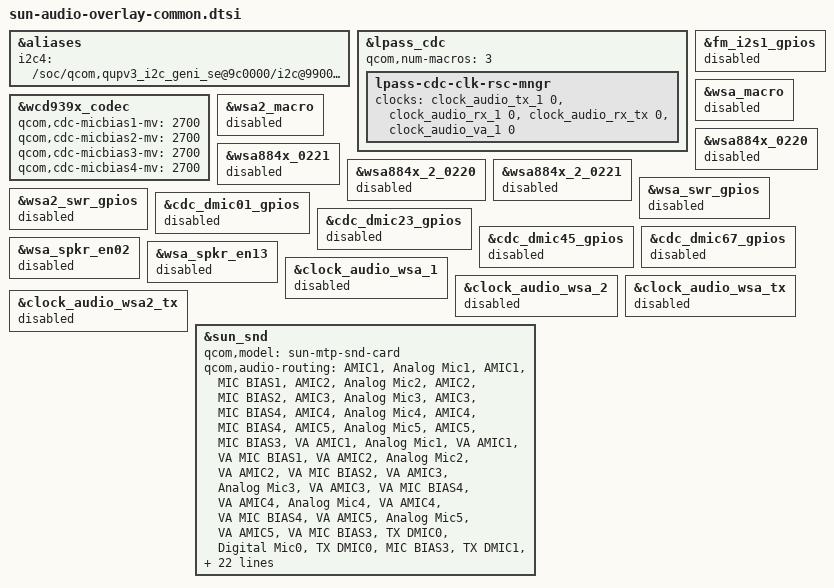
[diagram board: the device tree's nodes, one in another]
&aliases {
	i2c4 = "/soc/qcom,qupv3_i2c_geni_se@9c0000/i2c@990000";
};

&lpass_cdc {
	qcom,num-macros = <3>;
	lpass-cdc-clk-rsc-mngr {
	clock-names = "tx_core_clk", "rx_core_clk", "rx_tx_core_clk", "va_core_clk";
	clocks = <&clock_audio_tx_1 0>, <&clock_audio_rx_1 0>,
		<&clock_audio_rx_tx 0>, <&clock_audio_va_1 0>;
	};
};

&wcd939x_codec {
	qcom,cdc-micbias1-mv = <2700>;
	qcom,cdc-micbias2-mv = <2700>;
	qcom,cdc-micbias3-mv = <2700>;
	qcom,cdc-micbias4-mv = <2700>;
};

&fm_i2s1_gpios {
	status = "disabled";
};

&wsa_macro {
	status = "disabled";
};

&wsa2_macro {
	status = "disabled";
};

&wsa884x_0220 {
	status = "disabled";
};

&wsa884x_0221 {
	status = "disabled";
};

&wsa884x_2_0220 {
	status = "disabled";
};

&wsa884x_2_0221 {
	status = "disabled";
};

&wsa_swr_gpios {
	status = "disabled";
};

&wsa2_swr_gpios {
	status = "disabled";
};

&cdc_dmic01_gpios {
	status = "disabled";
};

&cdc_dmic23_gpios {
	status = "disabled";
};

&cdc_dmic45_gpios {
	status = "disabled";
};

&cdc_dmic67_gpios {
	status = "disabled";
};

&wsa_spkr_en02 {
	status = "disabled";
};

&wsa_spkr_en13 {
	status = "disabled";
};

&clock_audio_wsa_1 {
	status = "disabled";
};

&clock_audio_wsa_2 {
	status = "disabled";
};

&clock_audio_wsa_tx {
	status = "disabled";
};

&clock_audio_wsa2_tx {
	status = "disabled";
};

&sun_snd {
	qcom,model = "sun-mtp-snd-card";
	qcom,audio-routing =
		"AMIC1", "Analog Mic1",
		"AMIC1", "MIC BIAS1",
		"AMIC2", "Analog Mic2",
		"AMIC2", "MIC BIAS2",
		"AMIC3", "Analog Mic3",
		"AMIC3", "MIC BIAS4",
		"AMIC4", "Analog Mic4",
		"AMIC4", "MIC BIAS4",
		"AMIC5", "Analog Mic5",
		"AMIC5", "MIC BIAS3",
		"VA AMIC1", "Analog Mic1",
		"VA AMIC1", "VA MIC BIAS1",
		"VA AMIC2", "Analog Mic2",
		"VA AMIC2", "VA MIC BIAS2",
		"VA AMIC3", "Analog Mic3",
		"VA AMIC3", "VA MIC BIAS4",
		"VA AMIC4", "Analog Mic4",
		"VA AMIC4", "VA MIC BIAS4",
		"VA AMIC5", "Analog Mic5",
		"VA AMIC5", "VA MIC BIAS3",
		"TX DMIC0", "Digital Mic0",
		"TX DMIC0", "MIC BIAS3",
		"TX DMIC1", "Digital Mic1",
		"TX DMIC1", "MIC BIAS3",
		"TX DMIC2", "Digital Mic2",
		"TX DMIC2", "MIC BIAS1",
		"TX DMIC3", "Digital Mic3",
		"TX DMIC3", "MIC BIAS1",
		"IN1_HPHL", "HPHL_OUT",
		"IN2_HPHR", "HPHR_OUT",
		"IN3_EAR", "AUX_OUT",
		"RX_TX DEC0_INP", "TX DEC0 MUX",
		"RX_TX DEC1_INP", "TX DEC1 MUX",
		"RX_TX DEC2_INP", "TX DEC2 MUX",
		"RX_TX DEC3_INP", "TX DEC3 MUX",
		"TX SWR_INPUT", "WCD_TX_OUTPUT",
		"VA SWR_INPUT", "VA_SWR_CLK",
		"VA SWR_INPUT", "WCD_TX_OUTPUT",
		"VA_AIF1 CAP", "VA_SWR_CLK",
		"VA_AIF2 CAP", "VA_SWR_CLK",
		"VA_AIF3 CAP", "VA_SWR_CLK",
		"VA DMIC0", "Digital Mic0",
		"VA DMIC1", "Digital Mic1",
		"VA DMIC2", "Digital Mic2",
		"VA DMIC3", "Digital Mic3",
		"VA DMIC0", "VA MIC BIAS3",
		"VA DMIC1", "VA MIC BIAS3",
		"VA DMIC2", "VA MIC BIAS1",
		"VA DMIC3", "VA MIC BIAS1";
	asoc-codec  = <&stub_codec>, <&lpass_cdc>,
		      <&wcd939x_codec>, <&swr_haptics>;
	asoc-codec-names = "msm-stub-codec.1", "lpass-cdc",
			   "wcd939x_codec", "swr-haptics";
	qcom,wsa-max-devs = <0>;
};

